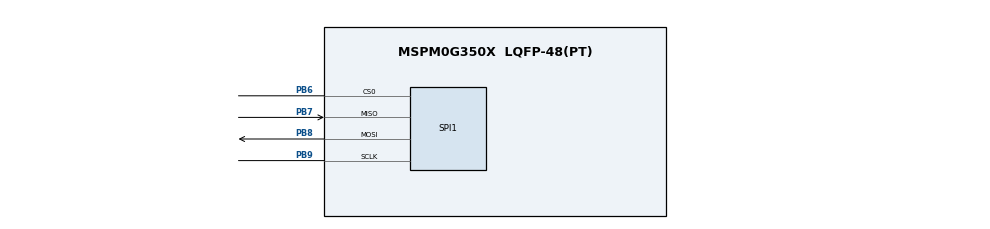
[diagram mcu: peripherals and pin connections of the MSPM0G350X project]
/**
 * @cliArgs --device "MSPM0G350X" --part "Default" --package "LQFP-48(PT)" --product "mspm0_sdk@2.10.00.04"
 * @versions {"tool":"1.27.0+4565"}
 */

/**
 * Import the modules used in this configuration.
 */
const Board  = scripting.addModule("/ti/driverlib/Board");
const GPIO   = scripting.addModule("/ti/driverlib/GPIO", {}, false);
const GPIO1  = GPIO.addInstance();
const GPIO2  = GPIO.addInstance();
const GPIO3  = GPIO.addInstance();
const GPIO4  = GPIO.addInstance();
const SPI    = scripting.addModule("/ti/driverlib/SPI", {}, false);
const SPI1   = SPI.addInstance();
const SYSCTL = scripting.addModule("/ti/driverlib/SYSCTL");
const TIMER  = scripting.addModule("/ti/driverlib/TIMER", {}, false);
const TIMER1 = TIMER.addInstance();
const UART   = scripting.addModule("/ti/driverlib/UART", {}, false);
const UART1  = UART.addInstance();

/**
 * Write custom configuration values to the imported modules.
 */
const gate4  = system.clockTree["EXCLKGATE"];
gate4.enable = true;

const pinFunction1 = system.clockTree["CLKOUT"];
scripting.suppress("The CLKOUT gate is enabled but the CLKOUT pin is not enabling the GPIO pin", pinFunction1, "enable");
scripting.suppress("The CLKOUT gate is enabled but the CLKOUT pin is not enabling the GPIO pin", pinFunction1, "enable");
scripting.suppress("The CLKOUT gate is enabled but the CLKOUT pin is not enabling the GPIO pin", pinFunction1, "enable");


GPIO1.$name                   = "gpioCS";
GPIO1.associatedPins[0].$name = "cspin";

GPIO2.$name                   = "gpioThermistor";
GPIO2.associatedPins[0].$name = "thermistor";

GPIO3.$name                   = "gpioRef";
GPIO3.associatedPins[0].$name = "reference";

GPIO4.$name                   = "gpioLED";
GPIO4.associatedPins[0].$name = "led1";

SPI1.$name                              = "mySPI";
SPI1.targetBitRate                      = 2000000;
SPI1.peripheral.sclkPin.$assign         = "PB9";
SPI1.peripheral.mosiPin.$assign         = "PB8";
SPI1.peripheral.misoPin.$assign         = "PB7";
SPI1.peripheral.cs0Pin.$assign          = "PB6";
SPI1.sclkPinConfig.$name                = "ti_driverlib_gpio_GPIOPinGeneric0";
SPI1.sclkPinConfig.direction            = scripting.forceWrite("OUTPUT");
SPI1.sclkPinConfig.onlyInternalResistor = scripting.forceWrite(false);
SPI1.sclkPinConfig.passedPeripheralType = scripting.forceWrite("Digital");
SPI1.mosiPinConfig.$name                = "ti_driverlib_gpio_GPIOPinGeneric1";
SPI1.mosiPinConfig.direction            = scripting.forceWrite("OUTPUT");
SPI1.mosiPinConfig.hideOutputInversion  = scripting.forceWrite(false);
SPI1.mosiPinConfig.onlyInternalResistor = scripting.forceWrite(false);
SPI1.mosiPinConfig.passedPeripheralType = scripting.forceWrite("Digital");
SPI1.misoPinConfig.$name                = "ti_driverlib_gpio_GPIOPinGeneric2";
SPI1.misoPinConfig.onlyInternalResistor = scripting.forceWrite(false);
SPI1.misoPinConfig.passedPeripheralType = scripting.forceWrite("Digital");
SPI1.cs0PinConfig.$name                 = "ti_driverlib_gpio_GPIOPinGeneric3";
SPI1.cs0PinConfig.direction             = scripting.forceWrite("OUTPUT");
SPI1.cs0PinConfig.hideOutputInversion   = scripting.forceWrite(false);
SPI1.cs0PinConfig.onlyInternalResistor  = scripting.forceWrite(false);
SPI1.cs0PinConfig.passedPeripheralType  = scripting.forceWrite("Digital");
SPI1.cs0PinConfig.enableConfig          = true;

SYSCTL.clockTreeEn = true;

TIMER1.$name     = "myTIMER";
TIMER1.timerMode = "PERIODIC_UP";

UART1.$name                            = "myUART";
UART1.targetBaudRate                   = 115200;
UART1.enabledInterrupts                = ["RX"];
UART1.peripheral.$assign               = "UART0";
UART1.txPinConfig.$name                = "ti_driverlib_gpio_GPIOPinGeneric4";
UART1.txPinConfig.direction            = scripting.forceWrite("OUTPUT");
UART1.txPinConfig.hideOutputInversion  = scripting.forceWrite(false);
UART1.txPinConfig.onlyInternalResistor = scripting.forceWrite(false);
UART1.txPinConfig.passedPeripheralType = scripting.forceWrite("Digital");
UART1.txPinConfig.enableConfig         = true;
UART1.rxPinConfig.$name                = "ti_driverlib_gpio_GPIOPinGeneric5";
UART1.rxPinConfig.hideOutputInversion  = scripting.forceWrite(false);
UART1.rxPinConfig.onlyInternalResistor = scripting.forceWrite(false);
UART1.rxPinConfig.passedPeripheralType = scripting.forceWrite("Digital");
UART1.rxPinConfig.enableConfig         = true;

/**
 * Pinmux solution for unlocked pins/peripherals. This ensures that minor changes to the automatic solver in a future
 * version of the tool will not impact the pinmux you originally saw.  These lines can be completely deleted in order to
 * re-solve from scratch.
 */
Board.peripheral.$suggestSolution            = "DEBUGSS";
Board.peripheral.swclkPin.$suggestSolution   = "PA20";
Board.peripheral.swdioPin.$suggestSolution   = "PA19";
GPIO1.associatedPins[0].pin.$suggestSolution = "PA28";
GPIO2.associatedPins[0].pin.$suggestSolution = "PA31";
GPIO3.associatedPins[0].pin.$suggestSolution = "PA2";
GPIO4.associatedPins[0].pin.$suggestSolution = "PA3";
SPI1.peripheral.$suggestSolution             = "SPI1";
TIMER1.peripheral.$suggestSolution           = "TIMA0";
UART1.peripheral.rxPin.$suggestSolution      = "PA1";
UART1.peripheral.txPin.$suggestSolution      = "PA0";
